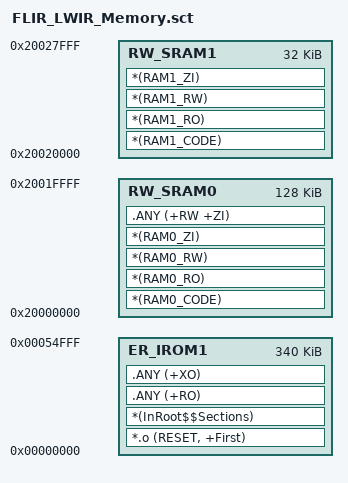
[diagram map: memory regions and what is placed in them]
; *************************************************************
; *** Scatter-Loading Description File for FLIR LWIR firmware ***
; *************************************************************
;
; SRAM0: 0x20000000..0x2001FFFF, default RW/ZI pool.
; SRAM1: 0x20020000..0x20027FFF, explicit fast/special pool.
;
; Select placement from C with section names:
;   RAM0_CODE / RAM1_CODE  - functions executed from SRAM
;   RAM0_RO   / RAM1_RO    - const data placed in SRAM
;   RAM0_RW   / RAM1_RW    - initialized data placed in SRAM
;   RAM0_ZI   / RAM1_ZI    - zero-initialized data placed in SRAM

LR_IROM1 0x00000000 0x00055000  {
  ER_IROM1 0x00000000 0x00055000  {
   *.o (RESET, +First)
   *(InRoot$$Sections)
   .ANY (+RO)
   .ANY (+XO)
  }

  RW_SRAM0 0x20000000 0x00020000  {
   *(RAM0_CODE)
   *(RAM0_RO)
   *(RAM0_RW)
   *(RAM0_ZI)
   .ANY (+RW +ZI)
  }

  RW_SRAM1 0x20020000 0x00008000  {
   *(RAM1_CODE)
   *(RAM1_RO)
   *(RAM1_RW)
   *(RAM1_ZI)
  }
}

